# ATSAMA5D27 register map
Vendor: Microchip Technology Inc.; File version: 1.0
CPU: CA5 r0p1, little endian, no MPU, no FPU, 4 interrupt priority bits
Address unit: 32 bits
Registers are 32-bit, read-write, reset 0x0 unless marked. A register's access mark holds for its fields unless they carry their own. Offsets are from the block's base; [hi:lo] are bit positions; {n}, {i} and the like mark numbered series; 'fields as' and 'values as' point back to an identical list.

## FLEXCOM0 — Flexible Serial Communication
Base 0xF8034000
Same registers: FLEXCOM1 0xF8038000, FLEXCOM2 0xFC010000, FLEXCOM3 0xFC014000, FLEXCOM4 0xFC018000
0x00 MR — FLEXCOM Mode Register
  [1:0] OPMODE — FLEXCOM Operating Mode
    0=NO_COM (No communication); 1=USART (All UART related protocols are selected (RS232, RS485, IrDA, ISO7816, LIN,)SPI/TWI related registers are not accessible and have no impact on IOs.); 2=SPI (SPI operating mode is selected.USART/TWI related registers are not accessible and have no impact on IOs.); 3=TWI (All TWI related protocols are selected (TWI, SMBus).USART/SPI related registers are not accessible and have no impact on IOs.)
0x10 RHR ro — FLEXCOM Receive Holding Register
  [15:0] RXDATA rw — Receive Data
0x20 THR — FLEXCOM Transmit Holding Register
  [15:0] TXDATA — Transmit Data
0x200 US_CR wo — USART Control Register
  [31] FIFODIS rw — FIFO Disable
  [30] FIFOEN rw — FIFO Enable
  [28] REQCLR rw — Request to Clear the Comparison Trigger
  [26] TXFLCLR rw — Transmit FIFO Lock CLEAR
  [25] RXFCLR rw — Receive FIFO Clear
  [24] TXFCLR rw — Transmit FIFO Clear
  [21] LINWKUP rw — Send LIN Wakeup Signal
  [20] LINABT rw — Abort LIN Transmission
  [19] RCS rw — Release SPI Chip Select
  [19] RTSDIS rw — Request to Send Disable
  [18] FCS rw — Force SPI Chip Select
  [18] RTSEN rw — Request to Send Enable
  [15] RETTO rw — Start Timeout Immediately
  [14] RSTNACK rw — Reset Non Acknowledge
  [13] RSTIT rw — Reset Iterations
  [12] SENDA rw — Send Address
  [11] STTTO rw — Clear TIMEOUT Flag and Start Timeout After Next Character Received
  [10] STPBRK rw — Stop Break
  [9] STTBRK rw — Start Break
  [8] RSTSTA rw — Reset Status Bits
  [7] TXDIS rw — Transmitter Disable
  [6] TXEN rw — Transmitter Enable
  [5] RXDIS rw — Receiver Disable
  [4] RXEN rw — Receiver Enable
  [3] RSTTX rw — Reset Transmitter
  [2] RSTRX rw — Reset Receiver
0x204 US_MR — USART Mode Register
  [31] ONEBIT — Start Frame Delimiter Selector
  [30] MODSYNC — Manchester Synchronization Mode
  [29] MAN — Manchester Encoder/Decoder Enable
  [28] FILTER — Receive Line Filter
  [26:24] MAX_ITERATION — Maximum Number of Automatic Iteration
  [23] INVDATA — Inverted Data
  [22] VAR_SYNC — Variable Synchronization of Command/Data Sync Start Frame Delimiter
  [21] DSNACK — Disable Successive NACK
  [20] INACK — Inhibit Non Acknowledge
  [20] WRDBT — Wait Read Data Before Transfer
  [19] OVER — Oversampling Mode
  [18] CLKO — Clock Output Select
  [17] MODE9 — 9-bit Character Length
  [16] CPOL — SPI Clock Polarity
  [16] MSBF — Bit Order
  [15:14] CHMODE — Channel Mode
    0=NORMAL (Normal mode); 1=AUTOMATIC (Automatic Echo. Receiver input is connected to the TXD pin.); 2=LOCAL_LOOPBACK (Local Loopback. Transmitter output is connected to the Receiver Input.); 3=REMOTE_LOOPBACK (Remote Loopback. RXD pin is internally connected to the TXD pin.)
  [13:12] NBSTOP — Number of Stop Bits
    0=1_BIT (1 stop bit); 1=1_5_BIT (1.5 stop bit (SYNC = 0) or reserved (SYNC = 1)); 2=2_BIT (2 stop bits)
  [11:9] PAR — Parity Type
    0=EVEN (Even parity); 1=ODD (Odd parity); 2=SPACE (Parity forced to 0 (Space)); 3=MARK (Parity forced to 1 (Mark)); 4=NO (No parity); 6=MULTIDROP (Multidrop mode)
  [8] CPHA — SPI Clock Phase
  [8] SYNC — Synchronous Mode Select
  [7:6] CHRL — Character Length
    3=8_BIT (Character length is 8 bits)
  [5:4] USCLKS — Clock Selection
    0=MCK (Peripheral clock is selected); 1=DIV (Peripheral clock Divided (DIV= 8) is selected); 2=GCLK (A PMC generic clock is selected); 3=SCK (External pin SCK is selected)
  [3:0] USART_MODE — USART Mode of Operation
    14=SPI_MASTER; 15=SPI_SLAVE
0x208 US_IER wo — USART Interrupt Enable Register
  [31] LINHTE rw — LIN Header Timeout Error Interrupt Enable
  [30] LINSTE rw — LIN Synch Tolerance Error Interrupt Enable
  [29] LINSNRE rw — LIN Slave Not Responding Error Interrupt Enable
  [28] LINCE rw — LIN Checksum Error Interrupt Enable
  [27] LINIPE rw — LIN Identifier Parity Interrupt Enable
  [26] LINISFE rw — LIN Inconsistent Synch Field Error Interrupt Enable
  [25] LINBE rw — LIN Bus Error Interrupt Enable
  [24] MANE rw — Manchester Error Interrupt Enable
  [22] CMP rw — Comparison Interrupt Enable
  [19] CTSIC rw — Clear to Send Input Change Interrupt Enable
  [19] NSSE rw — NSS Line (Driving CTS Pin) Rising or Falling Edge Event
  [15] LINTC rw — LIN Transfer Completed Interrupt Enable
  [14] LINID rw — LIN Identifier Sent or LIN Identifier Received Interrupt Enable
  [13] LINBK rw — LIN Break Sent or LIN Break Received Interrupt Enable
  [13] NACK rw — Non Acknowledge Interrupt Enable
  [10] ITER rw — Max number of Repetitions Reached Interrupt Enable
  [10] UNRE rw — SPI Underrun Error Interrupt Enable
  [9] TXEMPTY rw — TXEMPTY Interrupt Enable
  [8] TIMEOUT rw — Timeout Interrupt Enable
  [7] PARE rw — Parity Error Interrupt Enable
  [6] FRAME rw — Framing Error Interrupt Enable
  [5] OVRE rw — Overrun Error Interrupt Enable
  [2] RXBRK rw — Receiver Break Interrupt Enable
  [1] TXRDY rw — TXRDY Interrupt Enable
  [0] RXRDY rw — RXRDY Interrupt Enable
0x20C US_IDR wo — USART Interrupt Disable Register
  [31] LINHTE rw — LIN Header Timeout Error Interrupt Disable
  [30] LINSTE rw — LIN Synch Tolerance Error Interrupt Disable
  [29] LINSNRE rw — LIN Slave Not Responding Error Interrupt Disable
  [28] LINCE rw — LIN Checksum Error Interrupt Disable
  [27] LINIPE rw — LIN Identifier Parity Interrupt Disable
  [26] LINISFE rw — LIN Inconsistent Synch Field Error Interrupt Disable
  [25] LINBE rw — LIN Bus Error Interrupt Disable
  [24] MANE rw — Manchester Error Interrupt Disable
  [22] CMP rw — Comparison Interrupt Disable
  [19] CTSIC rw — Clear to Send Input Change Interrupt Disable
  [19] NSSE rw — NSS Line (Driving CTS Pin) Rising or Falling Edge Event
  [15] LINTC rw — LIN Transfer Completed Interrupt Disable
  [14] LINID rw — LIN Identifier Sent or LIN Identifier Received Interrupt Disable
  [13] LINBK rw — LIN Break Sent or LIN Break Received Interrupt Disable
  [13] NACK rw — Non Acknowledge Interrupt Disable
  [10] ITER rw — Max Number of Repetitions Reached Interrupt Disable
  [10] UNRE rw — SPI Underrun Error Interrupt Disable
  [9] TXEMPTY rw — TXEMPTY Interrupt Disable
  [8] TIMEOUT rw — Timeout Interrupt Disable
  [7] PARE rw — Parity Error Interrupt Disable
  [6] FRAME rw — Framing Error Interrupt Disable
  [5] OVRE rw — Overrun Error Interrupt Disable
  [2] RXBRK rw — Receiver Break Interrupt Disable
  [1] TXRDY rw — TXRDY Interrupt Disable
  [0] RXRDY rw — RXRDY Interrupt Disable
0x210 US_IMR ro — USART Interrupt Mask Register
  [31] LINHTE rw — LIN Header Timeout Error Interrupt Mask
  [30] LINSTE rw — LIN Synch Tolerance Error Interrupt Mask
  [29] LINSNRE rw — LIN Slave Not Responding Error Interrupt Mask
  [28] LINCE rw — LIN Checksum Error Interrupt Mask
  [27] LINIPE rw — LIN Identifier Parity Interrupt Mask
  [26] LINISFE rw — LIN Inconsistent Synch Field Error Interrupt Mask
  [25] LINBE rw — LIN Bus Error Interrupt Mask
  [24] MANE rw — Manchester Error Interrupt Mask
  [22] CMP rw — Comparison Interrupt Mask
  [19] CTSIC rw — Clear to Send Input Change Interrupt Mask
  [19] NSSE rw — NSS Line (Driving CTS Pin) Rising or Falling Edge Event
  [15] LINTC rw — LIN Transfer Completed Interrupt Mask
  [14] LINID rw — LIN Identifier Sent or LIN Identifier Received Interrupt Mask
  [13] LINBK rw — LIN Break Sent or LIN Break Received Interrupt Mask
  [13] NACK rw — Non Acknowledge Interrupt Mask
  [10] ITER rw — Max Number of Repetitions Reached Interrupt Mask
  [10] UNRE rw — SPI Underrun Error Interrupt Mask
  [9] TXEMPTY rw — TXEMPTY Interrupt Mask
  [8] TIMEOUT rw — Timeout Interrupt Mask
  [7] PARE rw — Parity Error Interrupt Mask
  [6] FRAME rw — Framing Error Interrupt Mask
  [5] OVRE rw — Overrun Error Interrupt Mask
  [2] RXBRK rw — Receiver Break Interrupt Mask
  [1] TXRDY rw — TXRDY Interrupt Mask
  [0] RXRDY rw — RXRDY Interrupt Mask
0x214 US_CSR ro — USART Channel Status Register
  [31] LINHTE rw — LIN Header Timeout Error
  [30] LINSTE rw — LIN Synch Tolerance Error
  [29] LINSNRE rw — LIN Slave Not Responding Error
  [28] LINCE rw — LIN Checksum Error
  [27] LINIPE rw — LIN Identifier Parity Error
  [26] LINISFE rw — LIN Inconsistent Synch Field Error
  [25] LINBE rw — LIN Bit Error
  [24] MANE rw — Manchester Error
  [23] CTS rw — Image of CTS Input
  [23] LINBLS rw — LIN Bus Line Status
  [23] NSS rw — NSS Line (Driving CTS Pin) Rising or Falling Edge Event (cleared on read)
  [22] CMP rw — Comparison Match
  [19] CTSIC rw — Clear to Send Input Change Flag
  [19] NSSE rw — NSS Line (Driving CTS Pin) Rising or Falling Edge Event (cleared on read)
  [15] LINTC rw — LIN Transfer Completed
  [14] LINID rw — LIN Identifier Sent or LIN Identifier Received
  [13] LINBK rw — LIN Break Sent or LIN Break Received
  [13] NACK rw — Non Acknowledge Interrupt
  [10] ITER rw — Max Number of Repetitions Reached
  [10] UNRE rw — Underrun Error
  [9] TXEMPTY rw — Transmitter Empty (cleared by writing FLEX_US_THR)
  [8] TIMEOUT rw — Receiver Timeout
  [7] PARE rw — Parity Error
  [6] FRAME rw — Framing Error
  [5] OVRE rw — Overrun Error
  [2] RXBRK rw — Break Received/End of Break
  [1] TXRDY rw — Transmitter Ready (cleared by writing FLEX_US_THR)
  [0] RXRDY rw — Receiver Ready (cleared by reading FLEX_US_RHR)
0x218 US_RHR ro — USART Receive Holding Register
  [8n+7:8n] RXCHR{n} rw (n=0..3) — Received Character
  [15] RXSYNH rw — Received Sync
  [8:0] RXCHR rw — Received Character
0x21C US_THR wo — USART Transmit Holding Register
  [8n+7:8n] TXCHR{n} rw (n=0..3) — Character to be Transmitted
  [15] TXSYNH rw — Sync Field to be Transmitted
  [8:0] TXCHR rw — Character to be Transmitted
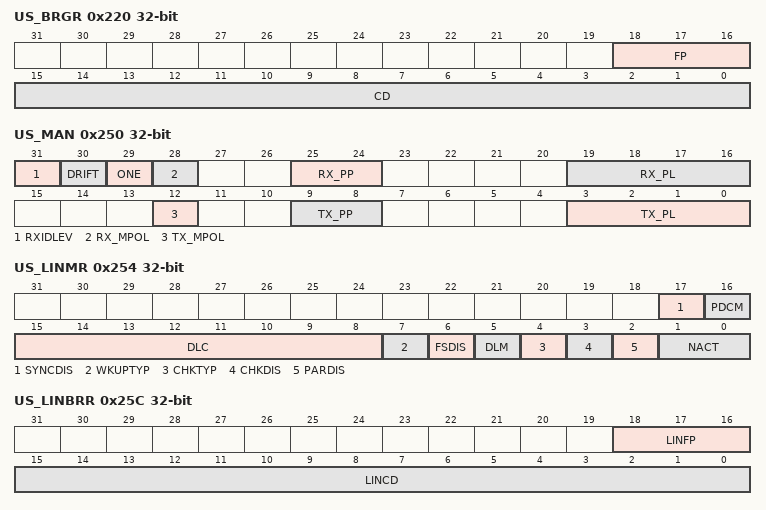
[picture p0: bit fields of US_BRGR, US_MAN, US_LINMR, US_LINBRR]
0x220 US_BRGR — USART Baud Rate Generator Register
  [18:16] FP — Fractional Part
  [15:0] CD — Clock Divider
0x224 US_RTOR — USART Receiver Timeout Register
  [16:0] TO — Timeout Value
0x228 US_TTGR — USART Transmitter Timeguard Register
  [7:0] TG — Timeguard Value
0x240 US_FIDI — USART FI DI Ratio Register
  [15:0] FI_DI_RATIO — FI Over DI Ratio Value
0x244 US_NER ro — USART Number of Errors Register
  [7:0] NB_ERRORS rw — Number of Errors
0x24C US_IF — USART IrDA Filter Register
  [7:0] IRDA_FILTER
0x250 US_MAN — USART Manchester Configuration Register
  [31] RXIDLEV — Receiver Idle Value
  [30] DRIFT — Drift Compensation
  [29] ONE — Must Be Set to 1
  [28] RX_MPOL — Receiver Manchester Polarity
  [25:24] RX_PP — Receiver Preamble Pattern detected
    0=ALL_ONE (The preamble is composed of '1's); 1=ALL_ZERO (The preamble is composed of '0's); 2=ZERO_ONE (The preamble is composed of '01's); 3=ONE_ZERO (The preamble is composed of '10's)
  [19:16] RX_PL — Receiver Preamble Length
  [12] TX_MPOL — Transmitter Manchester Polarity
  [9:8] TX_PP — Transmitter Preamble Pattern
    values as RX_PP
  [3:0] TX_PL — Transmitter Preamble Length
0x254 US_LINMR — USART LIN Mode Register
  [17] SYNCDIS — Synchronization Disable
  [16] PDCM — DMAC Mode
  [15:8] DLC — Data Length Control
  [7] WKUPTYP — Wakeup Signal Type
  [6] FSDIS — Frame Slot Mode Disable
  [5] DLM — Data Length Mode
  [4] CHKTYP — Checksum Type
  [3] CHKDIS — Checksum Disable
  [2] PARDIS — Parity Disable
  [1:0] NACT — LIN Node Action
    0=PUBLISH (The USART transmits the response.); 1=SUBSCRIBE (The USART receives the response.); 2=IGNORE (The USART does not transmit and does not receive the response.)
0x258 US_LINIR — USART LIN Identifier Register
  [7:0] IDCHR — Identifier Character
0x25C US_LINBRR ro — USART LIN Baud Rate Register
  [18:16] LINFP rw — Fractional Part after Synchronization
  [15:0] LINCD rw — Clock Divider after Synchronization
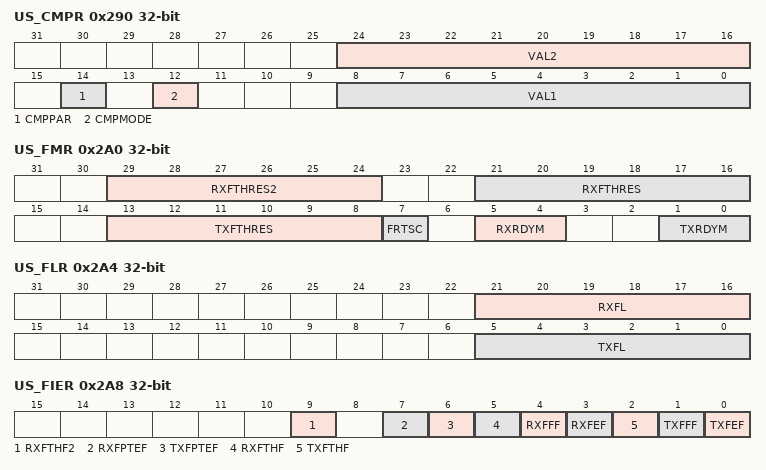
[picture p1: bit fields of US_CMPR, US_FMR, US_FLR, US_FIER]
0x290 US_CMPR — USART Comparison Register
  [24:16] VAL2 — Second Comparison Value for Received Character
  [14] CMPPAR — Compare Parity
  [12] CMPMODE — Comparison Mode
    0=FLAG_ONLY (Any character is received and comparison function drives CMP flag.); 1=START_CONDITION (Comparison condition must be met to start reception.)
  [8:0] VAL1 — First Comparison Value for Received Character
0x2A0 US_FMR — USART FIFO Mode Register
  [29:24] RXFTHRES2 — Receive FIFO Threshold 2
  [21:16] RXFTHRES — Receive FIFO Threshold
  [13:8] TXFTHRES — Transmit FIFO Threshold
  [7] FRTSC — FIFO RTS Pin Control enable (Hardware Handshaking mode only)
  [5:4] RXRDYM — Receiver Ready Mode
    0=ONE_DATA (RXRDY will be at level '1' when at least one unread data is in the Receive FIFO); 1=TWO_DATA (RXRDY will be at level '1' when at least two unread data are in the Receive FIFO); 2=FOUR_DATA (RXRDY will be at level '1' when at least four unread data are in the Receive FIFO)
  [1:0] TXRDYM — Transmitter Ready Mode
    0=ONE_DATA (TXRDY will be at level '1' when at least one data can be written in the Transmit FIFO); 1=TWO_DATA (TXRDY will be at level '1' when at least two data can be written in the Transmit FIFO); 2=FOUR_DATA (TXRDY will be at level '1' when at least four data can be written in the Transmit FIFO)
0x2A4 US_FLR ro — USART FIFO Level Register
  [21:16] RXFL rw — Receive FIFO Level
  [5:0] TXFL rw — Transmit FIFO Level
0x2A8 US_FIER wo — USART FIFO Interrupt Enable Register
  [9] RXFTHF2 rw — RXFTHF2 Interrupt Enable
  [7] RXFPTEF rw — RXFPTEF Interrupt Enable
  [6] TXFPTEF rw — TXFPTEF Interrupt Enable
  [5] RXFTHF rw — RXFTHF Interrupt Enable
  [4] RXFFF rw — RXFFF Interrupt Enable
  [3] RXFEF rw — RXFEF Interrupt Enable
  [2] TXFTHF rw — TXFTHF Interrupt Enable
  [1] TXFFF rw — TXFFF Interrupt Enable
  [0] TXFEF rw — TXFEF Interrupt Enable
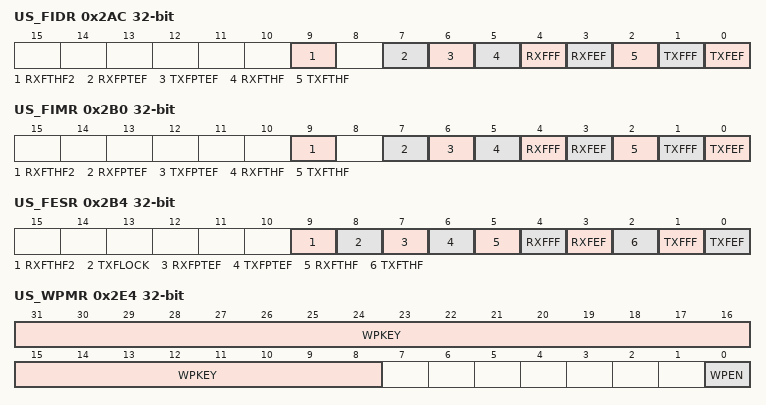
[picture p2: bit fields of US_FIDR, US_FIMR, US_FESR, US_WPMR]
0x2AC US_FIDR wo — USART FIFO Interrupt Disable Register
  [9] RXFTHF2 rw — RXFTHF2 Interrupt Disable
  [7] RXFPTEF rw — RXFPTEF Interrupt Disable
  [6] TXFPTEF rw — TXFPTEF Interrupt Disable
  [5] RXFTHF rw — RXFTHF Interrupt Disable
  [4] RXFFF rw — RXFFF Interrupt Disable
  [3] RXFEF rw — RXFEF Interrupt Disable
  [2] TXFTHF rw — TXFTHF Interrupt Disable
  [1] TXFFF rw — TXFFF Interrupt Disable
  [0] TXFEF rw — TXFEF Interrupt Disable
0x2B0 US_FIMR ro — USART FIFO Interrupt Mask Register
  [9] RXFTHF2 rw — RXFTHF2 Interrupt Mask
  [7] RXFPTEF rw — RXFPTEF Interrupt Mask
  [6] TXFPTEF rw — TXFPTEF Interrupt Mask
  [5] RXFTHF rw — RXFTHF Interrupt Mask
  [4] RXFFF rw — RXFFF Interrupt Mask
  [3] RXFEF rw — RXFEF Interrupt Mask
  [2] TXFTHF rw — TXFTHF Interrupt Mask
  [1] TXFFF rw — TXFFF Interrupt Mask
  [0] TXFEF rw — TXFEF Interrupt Mask
0x2B4 US_FESR ro — USART FIFO Event Status Register
  [9] RXFTHF2 rw — Receive FIFO Threshold Flag 2 (cleared by writing the FLEX_US_CR.RSTSTA bit)
  [8] TXFLOCK rw — Transmit FIFO Lock
  [7] RXFPTEF rw — Receive FIFO Pointer Error Flag
  [6] TXFPTEF rw — Transmit FIFO Pointer Error Flag
  [5] RXFTHF rw — Receive FIFO Threshold Flag (cleared by writing the FLEX_US_CR.RSTSTA bit)
  [4] RXFFF rw — Receive FIFO Full Flag (cleared by writing the FLEX_US_CR.RSTSTA bit)
  [3] RXFEF rw — Receive FIFO Empty Flag (cleared by writing the FLEX_US_CR.RSTSTA bit)
  [2] TXFTHF rw — Transmit FIFO Threshold Flag (cleared by writing the FLEX_US_CR.RSTSTA bit)
  [1] TXFFF rw — Transmit FIFO Full Flag (cleared by writing the FLEX_US_CR.RSTSTA bit)
  [0] TXFEF rw — Transmit FIFO Empty Flag (cleared by writing the FLEX_US_CR.RSTSTA bit)
0x2E4 US_WPMR — USART Write Protection Mode Register
  [31:8] WPKEY — Write Protection Key
    0x555341=PASSWD (Writing any other value in this field aborts the write operation of bit WPEN. Always reads as 0.)
  [0] WPEN — Write Protection Enable
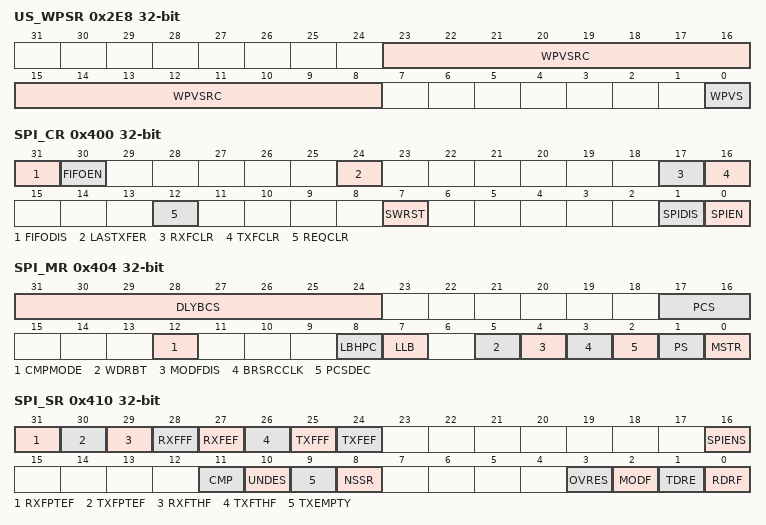
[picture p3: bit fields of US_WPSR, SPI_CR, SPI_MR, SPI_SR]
0x2E8 US_WPSR ro — USART Write Protection Status Register
  [23:8] WPVSRC rw — Write Protection Violation Source
  [0] WPVS rw — Write Protection Violation Status
0x400 SPI_CR wo — SPI Control Register
  [31] FIFODIS rw — FIFO Disable
  [30] FIFOEN rw — FIFO Enable
  [24] LASTXFER rw — Last Transfer
  [17] RXFCLR rw — Receive FIFO Clear
  [16] TXFCLR rw — Transmit FIFO Clear
  [12] REQCLR rw — Request to Clear the Comparison Trigger
  [7] SWRST rw — SPI Software Reset
  [1] SPIDIS rw — SPI Disable
  [0] SPIEN rw — SPI Enable
0x404 SPI_MR — SPI Mode Register
  [31:24] DLYBCS — Delay Between Chip Selects
  [17:16] PCS — Peripheral Chip Select
  [12] CMPMODE — Comparison Mode
    0=FLAG_ONLY (Any character is received and comparison function drives CMP flag.); 1=START_CONDITION (Comparison condition must be met to start reception of all incoming characters until REQCLR is set.)
  [8] LBHPC — Last Bit Half Period Compatibility
  [7] LLB — Local Loopback Enable
  [5] WDRBT — Wait Data Read Before Transfer
  [4] MODFDIS — Mode Fault Detection
  [3] BRSRCCLK — Bit Rate Source Clock
    0=PERIPH_CLK (The peripheral clock is the source clock for the bit rate generation.); 1=GCLK (GCLK is the source clock for the bit rate generation, thus the bit rate can be independent of the core/peripheral clock.)
  [2] PCSDEC — Chip Select Decode
  [1] PS — Peripheral Select
  [0] MSTR — Master/Slave Mode
0x408 SPI_RDR ro — SPI Receive Data Register
  [8n+7:8n] RD8_{n} rw (n=0..3) — Receive Data
  [19:16] PCS rw — Peripheral Chip Select
  [31:16] RD16_1 rw — Receive Data
  [15:0] RD rw — Receive Data
  [15:0] RD16_0 rw — Receive Data
0x40C SPI_TDR wo — SPI Transmit Data Register
  [24] LASTXFER rw — Last Transfer
  [19:16] PCS rw — Peripheral Chip Select
  [31:16] TD1 rw — Transmit Data
  [15:0] TD rw — Transmit Data
  [15:0] TD0 rw — Transmit Data
0x410 SPI_SR ro — SPI Status Register
  [31] RXFPTEF rw — Receive FIFO Pointer Error Flag
  [30] TXFPTEF rw — Transmit FIFO Pointer Error Flag
  [29] RXFTHF rw — Receive FIFO Threshold Flag
  [28] RXFFF rw — Receive FIFO Full Flag
  [27] RXFEF rw — Receive FIFO Empty Flag
  [26] TXFTHF rw — Transmit FIFO Threshold Flag (cleared on read)
  [25] TXFFF rw — Transmit FIFO Full Flag (cleared on read)
  [24] TXFEF rw — Transmit FIFO Empty Flag (cleared on read)
  [16] SPIENS rw — SPI Enable Status
  [11] CMP rw — Comparison Status (cleared on read)
  [10] UNDES rw — Underrun Error Status (Slave mode only) (cleared on read)
  [9] TXEMPTY rw — Transmission Registers Empty (cleared by writing FLEX_SPI_TDR)
  [8] NSSR rw — NSS Rising (cleared on read)
  [3] OVRES rw — Overrun Error Status (cleared on read)
  [2] MODF rw — Mode Fault Error (cleared on read)
  [1] TDRE rw — Transmit Data Register Empty (cleared by writing FLEX_SPI_TDR)
  [0] RDRF rw — Receive Data Register Full (cleared by reading FLEX_SPI_RDR)
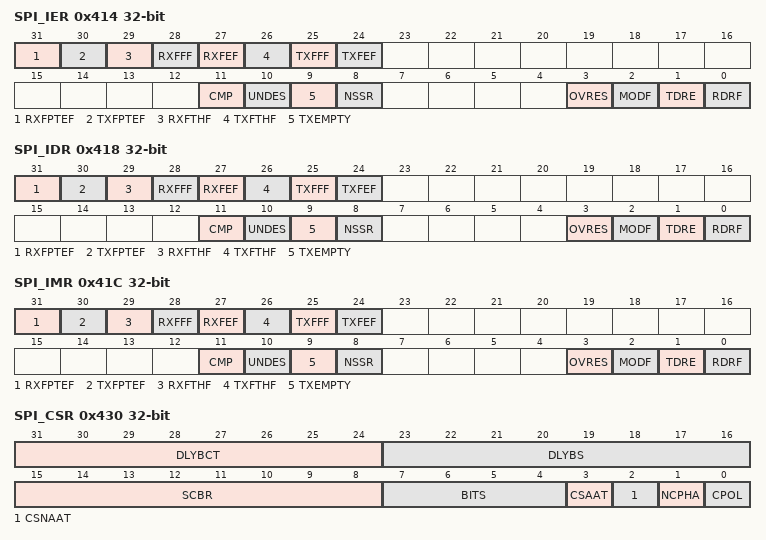
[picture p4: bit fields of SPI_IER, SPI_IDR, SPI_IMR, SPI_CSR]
0x414 SPI_IER wo — SPI Interrupt Enable Register
  [31] RXFPTEF rw — RXFPTEF Interrupt Enable
  [30] TXFPTEF rw — TXFPTEF Interrupt Enable
  [29] RXFTHF rw — RXFTHF Interrupt Enable
  [28] RXFFF rw — RXFFF Interrupt Enable
  [27] RXFEF rw — RXFEF Interrupt Enable
  [26] TXFTHF rw — TXFTHF Interrupt Enable
  [25] TXFFF rw — TXFFF Interrupt Enable
  [24] TXFEF rw — TXFEF Interrupt Enable
  [11] CMP rw — Comparison Interrupt Enable
  [10] UNDES rw — Underrun Error Interrupt Enable
  [9] TXEMPTY rw — Transmission Registers Empty Enable
  [8] NSSR rw — NSS Rising Interrupt Enable
  [3] OVRES rw — Overrun Error Interrupt Enable
  [2] MODF rw — Mode Fault Error Interrupt Enable
  [1] TDRE rw — SPI Transmit Data Register Empty Interrupt Enable
  [0] RDRF rw — Receive Data Register Full Interrupt Enable
0x418 SPI_IDR wo — SPI Interrupt Disable Register
  [31] RXFPTEF rw — RXFPTEF Interrupt Disable
  [30] TXFPTEF rw — TXFPTEF Interrupt Disable
  [29] RXFTHF rw — RXFTHF Interrupt Disable
  [28] RXFFF rw — RXFFF Interrupt Disable
  [27] RXFEF rw — RXFEF Interrupt Disable
  [26] TXFTHF rw — TXFTHF Interrupt Disable
  [25] TXFFF rw — TXFFF Interrupt Disable
  [24] TXFEF rw — TXFEF Interrupt Disable
  [11] CMP rw — Comparison Interrupt Disable
  [10] UNDES rw — Underrun Error Interrupt Disable
  [9] TXEMPTY rw — Transmission Registers Empty Disable
  [8] NSSR rw — NSS Rising Interrupt Disable
  [3] OVRES rw — Overrun Error Interrupt Disable
  [2] MODF rw — Mode Fault Error Interrupt Disable
  [1] TDRE rw — SPI Transmit Data Register Empty Interrupt Disable
  [0] RDRF rw — Receive Data Register Full Interrupt Disable
0x41C SPI_IMR ro — SPI Interrupt Mask Register
  [31] RXFPTEF rw — RXFPTEF Interrupt Mask
  [30] TXFPTEF rw — TXFPTEF Interrupt Mask
  [29] RXFTHF rw — RXFTHF Interrupt Mask
  [28] RXFFF rw — RXFFF Interrupt Mask
  [27] RXFEF rw — RXFEF Interrupt Mask
  [26] TXFTHF rw — TXFTHF Interrupt Mask
  [25] TXFFF rw — TXFFF Interrupt Mask
  [24] TXFEF rw — TXFEF Interrupt Mask
  [11] CMP rw — Comparison Interrupt Mask
  [10] UNDES rw — Underrun Error Interrupt Mask
  [9] TXEMPTY rw — Transmission Registers Empty Mask
  [8] NSSR rw — NSS Rising Interrupt Mask
  [3] OVRES rw — Overrun Error Interrupt Mask
  [2] MODF rw — Mode Fault Error Interrupt Mask
  [1] TDRE rw — SPI Transmit Data Register Empty Interrupt Mask
  [0] RDRF rw — Receive Data Register Full Interrupt Mask
0x430 SPI_CSR — SPI Chip Select Register
  [31:24] DLYBCT — Delay Between Consecutive Transfers
  [23:16] DLYBS — Delay Before SPCK
  [15:8] SCBR — Serial Clock Bit Rate
  [7:4] BITS — Bits Per Transfer
    {v}={v+8}_BIT ({v+8} bits for transfer) (v=0..8)
  [3] CSAAT — Chip Select Active After Transfer
  [2] CSNAAT — Chip Select Not Active After Transfer (Ignored if CSAAT = 1)
  [1] NCPHA — Clock Phase
  [0] CPOL — Clock Polarity
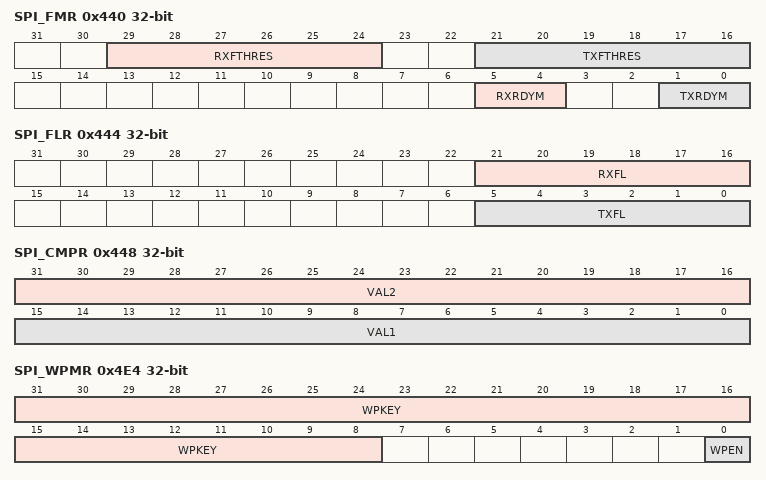
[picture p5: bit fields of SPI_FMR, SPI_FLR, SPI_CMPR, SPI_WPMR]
0x440 SPI_FMR — SPI FIFO Mode Register
  [29:24] RXFTHRES — Receive FIFO Threshold
  [21:16] TXFTHRES — Transmit FIFO Threshold
  [5:4] RXRDYM — Receive Data Register Full Mode
    0=ONE_DATA (RDRF will be at level '1' when at least one unread data is in the Receive FIFO.); 1=TWO_DATA (RDRF will be at level '1' when at least two unread data are in the Receive FIFO.Cannot be used if FLEX_SPI_MR.PS =1.); 2=FOUR_DATA (RDRF will be at level '1' when at least four unread data are in the Receive FIFO.Cannot be used when FLEX_SPI_CSRx.BITS is greater than 0, or if FLEX_SPI_MR.MSTR =1, or if FLEX_SPI_MR.PS =1.)
  [1:0] TXRDYM — Transmit Data Register Empty Mode
    0=ONE_DATA (TDRE will be at level '1' when at least one data can be written in the Transmit FIFO.); 1=TWO_DATA (TDRE will be at level '1' when at least two data can be written in the Transmit FIFO.Cannot be used if FLEX_SPI_MR.PS =1.)
0x444 SPI_FLR ro — SPI FIFO Level Register
  fields as US_FLR
0x448 SPI_CMPR — SPI Comparison Register
  [31:16] VAL2 — Second Comparison Value for Received Character
  [15:0] VAL1 — First Comparison Value for Received Character
0x4E4 SPI_WPMR — SPI Write Protection Mode Register
  [31:8] WPKEY — Write Protection Key
    0x535049=PASSWD (Writing any other value in this field aborts the write operation of bit WPEN.Always reads as 0)
  [0] WPEN — Write Protection Enable
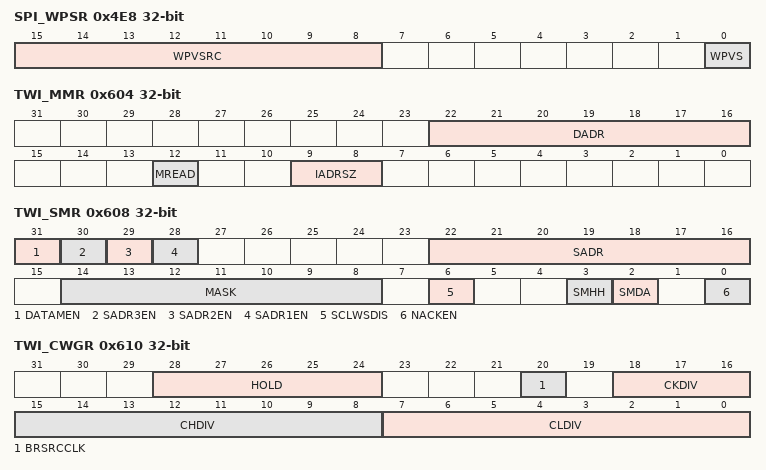
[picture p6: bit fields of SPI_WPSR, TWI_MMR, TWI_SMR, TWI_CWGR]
0x4E8 SPI_WPSR ro — SPI Write Protection Status Register
  [15:8] WPVSRC rw — Write Protection Violation Source
  [0] WPVS rw — Write Protection Violation Status
0x600 TWI_CR wo — TWI Control Register
  [29] FIFODIS rw — FIFO Disable
  [28] FIFOEN rw — FIFO Enable
  [26] LOCKCLR rw — Lock Clear
  [26] TXFLCLR rw — Transmit FIFO Lock CLEAR
  [25] RXFCLR rw — Receive FIFO Clear
  [24] THRCLR rw — Transmit Holding Register Clear
  [24] TXFCLR rw — Transmit FIFO Clear
  [17] ACMDIS rw — Alternative Command Mode Disable
  [16] ACMEN rw — Alternative Command Mode Enable
  [15] CLEAR rw — Bus CLEAR Command
  [14] PECRQ rw — PEC Request
  [13] PECDIS rw — Packet Error Checking Disable
  [12] PECEN rw — Packet Error Checking Enable
  [11] SMBDIS rw — SMBus Mode Disabled
  [10] SMBEN rw — SMBus Mode Enabled
  [9] HSDIS rw — TWI High-Speed Mode Disabled
  [8] HSEN rw — TWI High-Speed Mode Enabled
  [7] SWRST rw — Software Reset
  [6] QUICK rw — SMBus Quick Command
  [5] SVDIS rw — TWI Slave Mode Disabled
  [4] SVEN rw — TWI Slave Mode Enabled
  [3] MSDIS rw — TWI Master Mode Disabled
  [2] MSEN rw — TWI Master Mode Enabled
  [1] STOP rw — Send a STOP Condition
  [0] START rw — Send a START Condition
0x604 TWI_MMR — TWI Master Mode Register
  [22:16] DADR — Device Address
  [12] MREAD — Master Read Direction
  [9:8] IADRSZ — Internal Device Address Size
    0=NONE (No internal device address); 1=1_BYTE (One-byte internal device address); 2=2_BYTE (Two-byte internal device address); 3=3_BYTE (Three-byte internal device address)
0x608 TWI_SMR — TWI Slave Mode Register
  [31] DATAMEN — Data Matching Enable
  [30] SADR3EN — Slave Address 3 Enable
  [29] SADR2EN — Slave Address 2 Enable
  [28] SADR1EN — Slave Address 1 Enable
  [22:16] SADR — Slave Address
  [14:8] MASK — Slave Address Mask
  [6] SCLWSDIS — Clock Wait State Disable
  [3] SMHH — SMBus Host Header
  [2] SMDA — SMBus Default Address
  [0] NACKEN — Slave Receiver Data Phase NACK Enable
0x60C TWI_IADR — TWI Internal Address Register
  [23:0] IADR — Internal Address
0x610 TWI_CWGR — TWI Clock Waveform Generator Register
  [28:24] HOLD — TWD Hold Time Versus TWCK Falling
  [20] BRSRCCLK — Bit Rate Source Clock
    values as SPI_MR.BRSRCCLK
  [18:16] CKDIV — Clock Divider
  [15:8] CHDIV — Clock High Divider
  [7:0] CLDIV — Clock Low Divider
0x620 TWI_SR ro — TWI Status Register
  [25] SDA rw — SDA Line Value
  [24] SCL rw — SCL Line Value
  [23] LOCK rw — TWI Lock Due to Frame Errors
  [23] TXFLOCK rw — Transmit FIFO Lock
  [21] SMBHHM rw — SMBus Host Header Address Match (cleared on read)
  [20] SMBDAM rw — SMBus Default Address Match (cleared on read)
  [19] PECERR rw — PEC Error (cleared on read)
  [18] TOUT rw — Timeout Error (cleared on read)
  [16] MCACK rw — Master Code Acknowledge (cleared on read)
  [11] EOSACC rw — End Of Slave Access (cleared on read)
  [10] SCLWS rw — Clock Wait State
  [9] ARBLST rw — Arbitration Lost (cleared on read)
  [8] NACK rw — Not Acknowledged (cleared on read)
  [7] UNRE rw — Underrun Error (cleared on read)
  [6] OVRE rw — Overrun Error (cleared on read)
  [5] GACC rw — General Call Access (cleared on read)
  [4] SVACC rw — Slave Access
  [3] SVREAD rw — Slave Read
  [2] TXRDY rw — Transmit Holding Register Ready (cleared by writing FLEX_TWI_THR)
  [1] RXRDY rw — Receive Holding Register Ready (cleared when reading FLEX_TWI_RHR)
  [0] TXCOMP rw — Transmission Completed (cleared by writing FLEX_TWI_THR)
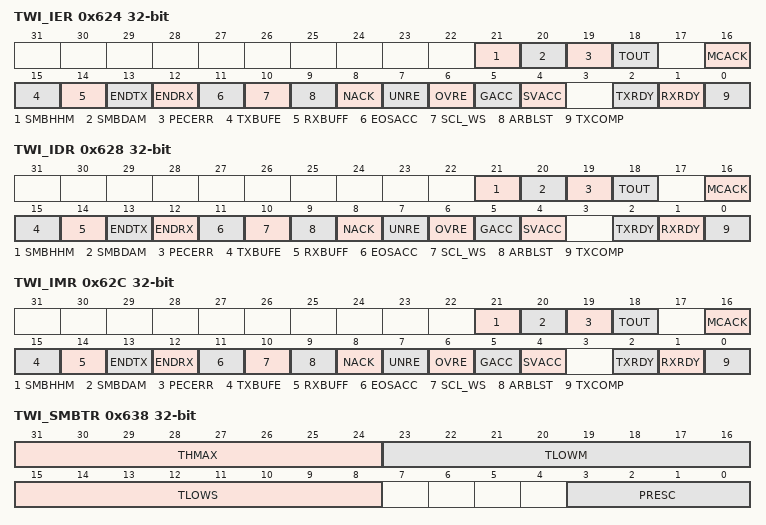
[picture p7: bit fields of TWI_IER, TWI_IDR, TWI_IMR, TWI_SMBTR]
0x624 TWI_IER wo — TWI Interrupt Enable Register
  [21] SMBHHM rw — SMBus Host Header Address Match Interrupt Enable
  [20] SMBDAM rw — SMBus Default Address Match Interrupt Enable
  [19] PECERR rw — PEC Error Interrupt Enable
  [18] TOUT rw — Timeout Error Interrupt Enable
  [16] MCACK rw — Master Code Acknowledge Interrupt Enable
  [15] TXBUFE rw — Transmit Buffer Empty Interrupt Enable
  [14] RXBUFF rw — Receive Buffer Full Interrupt Enable
  [13] ENDTX rw — End of Transmit Buffer Interrupt Enable
  [12] ENDRX rw — End of Receive Buffer Interrupt Enable
  [11] EOSACC rw — End Of Slave Access Interrupt Enable
  [10] SCL_WS rw — Clock Wait State Interrupt Enable
  [9] ARBLST rw — Arbitration Lost Interrupt Enable
  [8] NACK rw — Not Acknowledge Interrupt Enable
  [7] UNRE rw — Underrun Error Interrupt Enable
  [6] OVRE rw — Overrun Error Interrupt Enable
  [5] GACC rw — General Call Access Interrupt Enable
  [4] SVACC rw — Slave Access Interrupt Enable
  [2] TXRDY rw — Transmit Holding Register Ready Interrupt Enable
  [1] RXRDY rw — Receive Holding Register Ready Interrupt Enable
  [0] TXCOMP rw — Transmission Completed Interrupt Enable
0x628 TWI_IDR wo — TWI Interrupt Disable Register
  [21] SMBHHM rw — SMBus Host Header Address Match Interrupt Disable
  [20] SMBDAM rw — SMBus Default Address Match Interrupt Disable
  [19] PECERR rw — PEC Error Interrupt Disable
  [18] TOUT rw — Timeout Error Interrupt Disable
  [16] MCACK rw — Master Code Acknowledge Interrupt Disable
  [15] TXBUFE rw — Transmit Buffer Empty Interrupt Disable
  [14] RXBUFF rw — Receive Buffer Full Interrupt Disable
  [13] ENDTX rw — End of Transmit Buffer Interrupt Disable
  [12] ENDRX rw — End of Receive Buffer Interrupt Disable
  [11] EOSACC rw — End Of Slave Access Interrupt Disable
  [10] SCL_WS rw — Clock Wait State Interrupt Disable
  [9] ARBLST rw — Arbitration Lost Interrupt Disable
  [8] NACK rw — Not Acknowledge Interrupt Disable
  [7] UNRE rw — Underrun Error Interrupt Disable
  [6] OVRE rw — Overrun Error Interrupt Disable
  [5] GACC rw — General Call Access Interrupt Disable
  [4] SVACC rw — Slave Access Interrupt Disable
  [2] TXRDY rw — Transmit Holding Register Ready Interrupt Disable
  [1] RXRDY rw — Receive Holding Register Ready Interrupt Disable
  [0] TXCOMP rw — Transmission Completed Interrupt Disable
0x62C TWI_IMR ro — TWI Interrupt Mask Register
  [21] SMBHHM rw — SMBus Host Header Address Match Interrupt Mask
  [20] SMBDAM rw — SMBus Default Address Match Interrupt Mask
  [19] PECERR rw — PEC Error Interrupt Mask
  [18] TOUT rw — Timeout Error Interrupt Mask
  [16] MCACK rw — Master Code Acknowledge Interrupt Mask
  [15] TXBUFE rw — Transmit Buffer Empty Interrupt Mask
  [14] RXBUFF rw — Receive Buffer Full Interrupt Mask
  [13] ENDTX rw — End of Transmit Buffer Interrupt Mask
  [12] ENDRX rw — End of Receive Buffer Interrupt Mask
  [11] EOSACC rw — End Of Slave Access Interrupt Mask
  [10] SCL_WS rw — Clock Wait State Interrupt Mask
  [9] ARBLST rw — Arbitration Lost Interrupt Mask
  [8] NACK rw — Not Acknowledge Interrupt Mask
  [7] UNRE rw — Underrun Error Interrupt Mask
  [6] OVRE rw — Overrun Error Interrupt Mask
  [5] GACC rw — General Call Access Interrupt Mask
  [4] SVACC rw — Slave Access Interrupt Mask
  [2] TXRDY rw — Transmit Holding Register Ready Interrupt Mask
  [1] RXRDY rw — Receive Holding Register Ready Interrupt Mask
  [0] TXCOMP rw — Transmission Completed Interrupt Mask
0x630 TWI_RHR ro — TWI Receive Holding Register
  [8n+7:8n] RXDATA{n} rw (n=0..3) — Master or Slave Receive Holding Data {n}
  [7:0] RXDATA rw — Master or Slave Receive Holding Data
0x634 TWI_THR wo — TWI Transmit Holding Register
  [8n+7:8n] TXDATA{n} rw (n=0..3) — Master or Slave Transmit Holding Data {n}
  [7:0] TXDATA rw — Master or Slave Transmit Holding Data
0x638 TWI_SMBTR — TWI SMBus Timing Register
  [31:24] THMAX — Clock High Maximum Cycles
  [23:16] TLOWM — Master Clock Stretch Maximum Cycles
  [15:8] TLOWS — Slave Clock Stretch Maximum Cycles
  [3:0] PRESC — SMBus Clock Prescaler
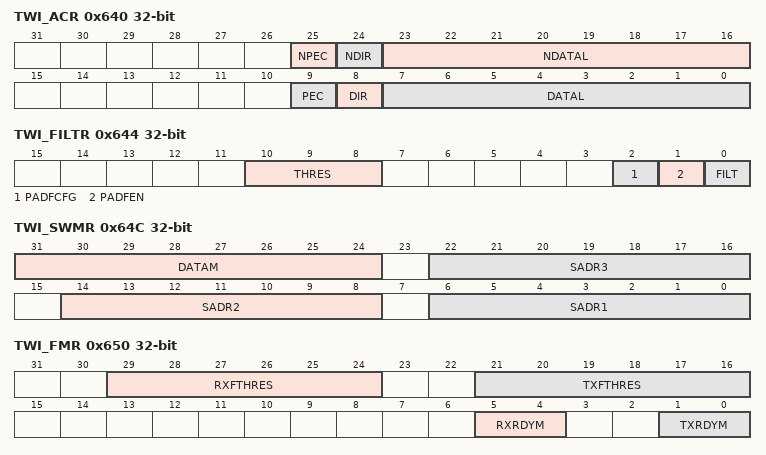
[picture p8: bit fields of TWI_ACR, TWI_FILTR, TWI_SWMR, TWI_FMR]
0x640 TWI_ACR — TWI Alternative Command Register
  [25] NPEC — Next PEC Request (SMBus Mode only)
  [24] NDIR — Next Transfer Direction
  [23:16] NDATAL — Next Data Length
  [9] PEC — PEC Request (SMBus Mode only)
  [8] DIR — Transfer Direction
  [7:0] DATAL — Data Length
0x644 TWI_FILTR — TWI Filter Register
  [10:8] THRES — Digital Filter Threshold
  [2] PADFCFG — PAD Filter Config
  [1] PADFEN — PAD Filter Enable
  [0] FILT — RX Digital Filter
0x64C TWI_SWMR — TWI SleepWalking Matching Register
  [31:24] DATAM — Data Match
  [22:16] SADR3 — Slave Address 3
  [14:8] SADR2 — Slave Address 2
  [6:0] SADR1 — Slave Address 1
0x650 TWI_FMR — TWI FIFO Mode Register
  [29:24] RXFTHRES — Receive FIFO Threshold
  [21:16] TXFTHRES — Transmit FIFO Threshold
  [5:4] RXRDYM — Receiver Ready Mode
    values as US_FMR.RXRDYM
  [1:0] TXRDYM — Transmitter Ready Mode
    values as US_FMR.TXRDYM
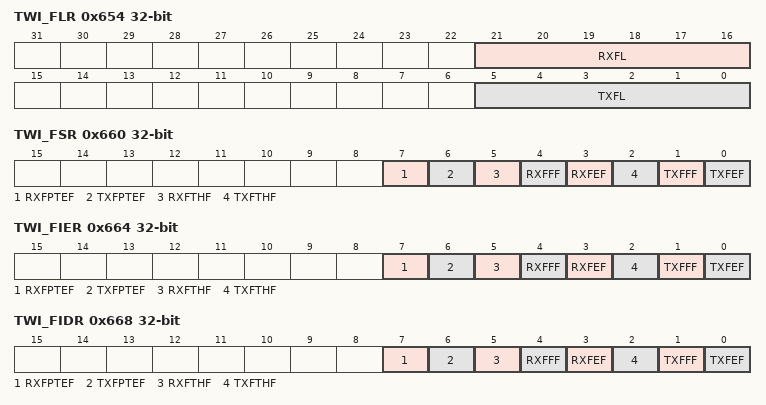
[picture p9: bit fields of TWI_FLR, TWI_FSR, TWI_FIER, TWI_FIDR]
0x654 TWI_FLR ro — TWI FIFO Level Register
  fields as US_FLR
0x660 TWI_FSR ro — TWI FIFO Status Register
  [7] RXFPTEF rw — Receive FIFO Pointer Error Flag
  [6] TXFPTEF rw — Transmit FIFO Pointer Error Flag
  [5] RXFTHF rw — Receive FIFO Threshold Flag
  [4] RXFFF rw — Receive FIFO Full Flag
  [3] RXFEF rw — Receive FIFO Empty Flag
  [2] TXFTHF rw — Transmit FIFO Threshold Flag (cleared on read)
  [1] TXFFF rw — Transmit FIFO Full Flag (cleared on read)
  [0] TXFEF rw — Transmit FIFO Empty Flag (cleared on read)
0x664 TWI_FIER wo — TWI FIFO Interrupt Enable Register
  [7] RXFPTEF rw — RXFPTEF Interrupt Enable
  [6] TXFPTEF rw — TXFPTEF Interrupt Enable
  [5] RXFTHF rw — RXFTHF Interrupt Enable
  [4] RXFFF rw — RXFFF Interrupt Enable
  [3] RXFEF rw — RXFEF Interrupt Enable
  [2] TXFTHF rw — TXFTHF Interrupt Enable
  [1] TXFFF rw — TXFFF Interrupt Enable
  [0] TXFEF rw — TXFEF Interrupt Enable
0x668 TWI_FIDR wo — TWI FIFO Interrupt Disable Register
  [7] RXFPTEF rw — RXFPTEF Interrupt Disable
  [6] TXFPTEF rw — TXFPTEF Interrupt Disable
  [5] RXFTHF rw — RXFTHF Interrupt Disable
  [4] RXFFF rw — RXFFF Interrupt Disable
  [3] RXFEF rw — RXFEF Interrupt Disable
  [2] TXFTHF rw — TXFTHF Interrupt Disable
  [1] TXFFF rw — TXFFF Interrupt Disable
  [0] TXFEF rw — TXFEF Interrupt Disable
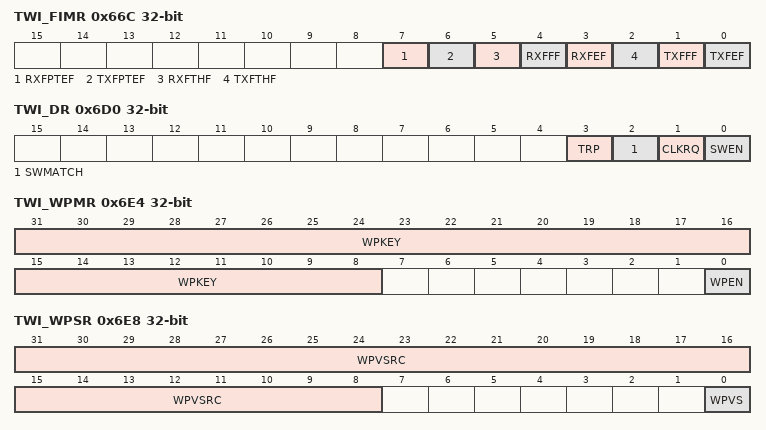
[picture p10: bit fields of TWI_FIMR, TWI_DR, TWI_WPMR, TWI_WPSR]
0x66C TWI_FIMR ro — TWI FIFO Interrupt Mask Register
  [7] RXFPTEF rw — RXFPTEF Interrupt Mask
  [6] TXFPTEF rw — TXFPTEF Interrupt Mask
  [5] RXFTHF rw — RXFTHF Interrupt Mask
  [4] RXFFF rw — RXFFF Interrupt Mask
  [3] RXFEF rw — RXFEF Interrupt Mask
  [2] TXFTHF rw — TXFTHF Interrupt Mask
  [1] TXFFF rw — TXFFF Interrupt Mask
  [0] TXFEF rw — TXFEF Interrupt Mask
0x6D0 TWI_DR ro — TWI Debug Register
  [3] TRP rw — Transfer Pending
  [2] SWMATCH rw — SleepWalking Match
  [1] CLKRQ rw — Clock Request
  [0] SWEN rw — SleepWalking Enable
0x6E4 TWI_WPMR — TWI Write Protection Mode Register
  [31:8] WPKEY — Write Protection Key
    0x545749=PASSWD (Writing any other value in this field aborts the write operation of bit WPEN.Always reads as 0)
  [0] WPEN — Write Protection Enable
0x6E8 TWI_WPSR ro — TWI Write Protection Status Register
  [31:8] WPVSRC rw — Write Protection Violation Source
  [0] WPVS rw — Write Protect Violation Status
